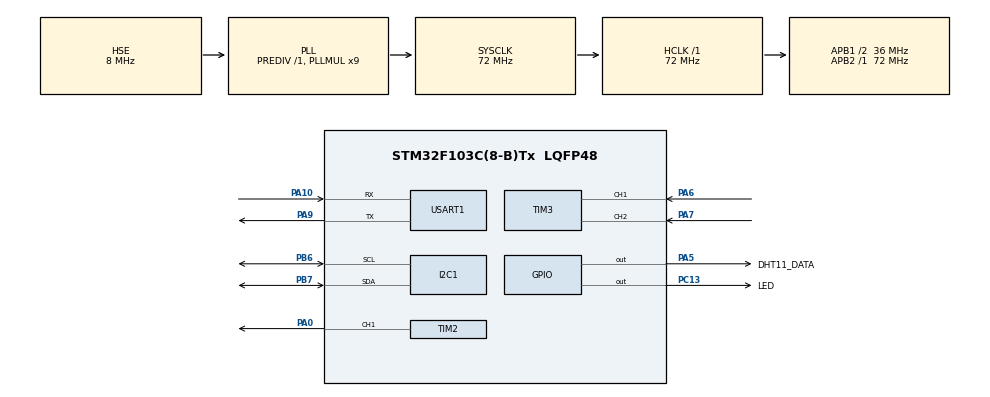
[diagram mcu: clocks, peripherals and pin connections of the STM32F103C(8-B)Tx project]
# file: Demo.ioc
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Dma.Request0=USART1_RX
Dma.Request1=USART1_TX
Dma.USART1_RX.0.Direction=DMA_PERIPH_TO_MEMORY
Dma.USART1_RX.0.Instance=DMA1_Channel5
Dma.USART1_RX.0.MemDataAlignment=DMA_MDATAALIGN_BYTE
Dma.USART1_RX.0.MemInc=DMA_MINC_ENABLE
Dma.USART1_RX.0.Mode=DMA_NORMAL
Dma.USART1_RX.0.PeriphDataAlignment=DMA_PDATAALIGN_BYTE
Dma.USART1_RX.0.PeriphInc=DMA_PINC_DISABLE
Dma.USART1_RX.0.Priority=DMA_PRIORITY_LOW
Dma.USART1_TX.1.Direction=DMA_MEMORY_TO_PERIPH
Dma.USART1_TX.1.Instance=DMA1_Channel4
Dma.USART1_TX.1.MemDataAlignment=DMA_MDATAALIGN_BYTE
Dma.USART1_TX.1.MemInc=DMA_MINC_ENABLE
Dma.USART1_TX.1.Mode=DMA_NORMAL
Dma.USART1_TX.1.PeriphDataAlignment=DMA_PDATAALIGN_BYTE
Dma.USART1_TX.1.PeriphInc=DMA_PINC_DISABLE
Dma.USART1_TX.1.Priority=DMA_PRIORITY_LOW
FREERTOS.BinarySemaphores01=Sem_UartRx,Dynamic,NULL,Available
FREERTOS.Mutexes01=Mutex_State,Dynamic,NULL,Available
FREERTOS.Queues01=Queue_ControlCmd,5,16,1,Dynamic,NULL,NULL
FREERTOS.Tasks01=Task_Safety,40,256,AppTask_Safety,Default,NULL,Dynamic,NULL,NULL;Task_MotorPID,32,256,AppTask_MotorPID,Default,NULL,Dynamic,NULL,NULL;Task_CommRX,24,256,AppTask_CommRX,Default,NULL,Dynamic,NULL,NULL;Task_Sensor,16,256,AppTask_Sensor,Default,NULL,Dynamic,NULL,NULL;Task_Status,8,256,AppTask_Status,Default,NULL,Dynamic,NULL,NULL
FREERTOS.configMINIMAL_STACK_SIZE=256
FREERTOS.configTOTAL_HEAP_SIZE=16384
Mcu.Family=STM32F1
Mcu.Name=STM32F103C(8-B)Tx
Mcu.Package=LQFP48
NVIC.DMA1_Channel4_IRQn=true\:5\:0\:false\:false\:true\:true\:false\:true\:true
NVIC.DMA1_Channel5_IRQn=true\:5\:0\:false\:false\:true\:true\:false\:true\:true
NVIC.PriorityGroup=NVIC_PRIORITYGROUP_4
NVIC.TIM1_UP_IRQn=true\:15\:0\:false\:false\:true\:false\:false\:true\:true
NVIC.TIM4_IRQn=true\:5\:0\:false\:false\:true\:true\:true\:true\:true
NVIC.TimeBase=TIM1_UP_IRQn
NVIC.TimeBaseIP=TIM1
NVIC.USART1_IRQn=true\:5\:0\:false\:false\:true\:true\:true\:true\:true
PA0-WKUP.Signal=S_TIM2_CH1_ETR
PA10.Mode=Asynchronous
PA10.Signal=USART1_RX
PA13.Mode=Serial_Wire
PA13.Signal=SYS_JTMS-SWDIO
PA14.Mode=Serial_Wire
PA14.Signal=SYS_JTCK-SWCLK
PA5.GPIO_Label=DHT11_DATA
PA5.GPIO_ModeDefaultOutputPP=GPIO_MODE_OUTPUT_OD
PA5.GPIO_PuPd=GPIO_PULLUP
PA5.Signal=GPIO_Output
PA6.Signal=S_TIM3_CH1
PA7.Signal=S_TIM3_CH2
PA9.Mode=Asynchronous
PA9.Signal=USART1_TX
PB6.Mode=I2C
PB6.Signal=I2C1_SCL
PB7.Mode=I2C
PB7.Signal=I2C1_SDA
PC13-TAMPER-RTC.GPIO_Label=LED
PC13-TAMPER-RTC.Signal=GPIO_Output
PD0-OSC_IN.Mode=HSE-External-Oscillator
PD0-OSC_IN.Signal=RCC_OSC_IN
PD1-OSC_OUT.Mode=HSE-External-Oscillator
PD1-OSC_OUT.Signal=RCC_OSC_OUT
ProjectManager.HeapSize=0x200
ProjectManager.StackSize=0x400
ProjectManager.TargetToolchain=CMake
RCC.AHBFreq_Value=72000000
RCC.APB1CLKDivider=RCC_HCLK_DIV2
RCC.APB1Freq_Value=36000000
RCC.APB1TimFreq_Value=72000000
RCC.APB2Freq_Value=72000000
RCC.APB2TimFreq_Value=72000000
RCC.HCLKFreq_Value=72000000
RCC.PLLMUL=RCC_PLL_MUL9
RCC.PLLSourceVirtual=RCC_PLLSOURCE_HSE
RCC.SYSCLKFreq_VALUE=72000000
RCC.SYSCLKSource=RCC_SYSCLKSOURCE_PLLCLK
RCC.USBFreq_Value=72000000
SH.S_TIM2_CH1_ETR.0=TIM2_CH1,PWM Generation1 CH1
SH.S_TIM3_CH1.0=TIM3_CH1,Encoder_Interface
SH.S_TIM3_CH2.0=TIM3_CH2,Encoder_Interface
TIM2.Channel-PWM\ Generation1\ CH1=TIM_CHANNEL_1
TIM2.Period=1000-1
TIM2.Prescaler=72-1
TIM3.EncoderMode=TIM_ENCODERMODE_TI12
USART1.VirtualMode=VM_ASYNC
VP_FREERTOS_VS_CMSIS_V2.Mode=CMSIS_V2
VP_SYS_VS_tim1.Mode=TIM1
VP_TIM2_VS_ClockSourceINT.Mode=Internal
VP_TIM4_VS_ClockSourceINT.Mode=Internal
board=custom

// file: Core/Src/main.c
/* USER CODE BEGIN Header */
/**
  ******************************************************************************
  * @file           : main.c
  * @brief          : Main program body
  ******************************************************************************
  * @attention
  *
  * Copyright (c) 2026 STMicroelectronics.
  * All rights reserved.
  *
  * This software is licensed under terms that can be found in the LICENSE file
  * in the root directory of this software component.
  * If no LICENSE file comes with this software, it is provided AS-IS.
  *
  ******************************************************************************
  */
/* USER CODE END Header */
#include "main.h"
#include "cmsis_os.h"
#include "dma.h"
#include "i2c.h"
#include "tim.h"
#include "usart.h"
#include "gpio.h"

/* USER CODE BEGIN Includes */
#include "app_main.h"
#include "motor.h"
/* USER CODE END Includes */

void SystemClock_Config(void);
void MX_FREERTOS_Init(void);

int main(void)
{

  /* MCU Configuration--------------------------------------------------------*/

  /* Reset of all peripherals, Initializes the Flash interface and the Systick. */
  HAL_Init();

  /* Configure the system clock */
  SystemClock_Config();

  /* Initialize all configured peripherals */
  MX_GPIO_Init();
  MX_DMA_Init();
  MX_I2C1_Init();
  MX_TIM2_Init();
  MX_TIM3_Init();
  MX_TIM4_Init();
  MX_USART1_UART_Init();
  /* USER CODE BEGIN 2 */
  App_Init();
  /* USER CODE END 2 */

  /* Init scheduler */
  osKernelInitialize();  /* Call init function for freertos objects (in cmsis_os2.c) */
  MX_FREERTOS_Init();

  /* Start scheduler */
  osKernelStart();

  /* We should never get here as control is now taken by the scheduler */

  /* Infinite loop */
  while (1)
  {

  }
}

void SystemClock_Config(void)
{
  RCC_OscInitTypeDef RCC_OscInitStruct = {0};
  RCC_ClkInitTypeDef RCC_ClkInitStruct = {0};

  /** Initializes the RCC Oscillators according to the specified parameters
  * in the RCC_OscInitTypeDef structure.
  */
  RCC_OscInitStruct.OscillatorType = RCC_OSCILLATORTYPE_HSE;
  RCC_OscInitStruct.HSEState = RCC_HSE_ON;
  RCC_OscInitStruct.HSEPredivValue = RCC_HSE_PREDIV_DIV1;
  RCC_OscInitStruct.HSIState = RCC_HSI_ON;
  RCC_OscInitStruct.PLL.PLLState = RCC_PLL_ON;
  RCC_OscInitStruct.PLL.PLLSource = RCC_PLLSOURCE_HSE;
  RCC_OscInitStruct.PLL.PLLMUL = RCC_PLL_MUL9;
  if (HAL_RCC_OscConfig(&RCC_OscInitStruct) != HAL_OK)
  {
    Error_Handler();
  }

  /** Initializes the CPU, AHB and APB buses clocks
  */
  RCC_ClkInitStruct.ClockType = RCC_CLOCKTYPE_HCLK|RCC_CLOCKTYPE_SYSCLK
                              |RCC_CLOCKTYPE_PCLK1|RCC_CLOCKTYPE_PCLK2;
  RCC_ClkInitStruct.SYSCLKSource = RCC_SYSCLKSOURCE_PLLCLK;
  RCC_ClkInitStruct.AHBCLKDivider = RCC_SYSCLK_DIV1;
  RCC_ClkInitStruct.APB1CLKDivider = RCC_HCLK_DIV2;
  RCC_ClkInitStruct.APB2CLKDivider = RCC_HCLK_DIV1;

  if (HAL_RCC_ClockConfig(&RCC_ClkInitStruct, FLASH_LATENCY_2) != HAL_OK)
  {
    Error_Handler();
  }
}

void HAL_TIM_PeriodElapsedCallback(TIM_HandleTypeDef *htim)
{
  if (htim->Instance == TIM1)
  {
    HAL_IncTick();
  }
  /* USER CODE BEGIN Callback 1 */
  if (htim->Instance == TIM4)
  {
    if (Motor_IsRunning() && !g_sys_state.system_fault)
    {
      Motor_PID_Update();
    }
  }
  /* USER CODE END Callback 1 */
}

void Error_Handler(void)
{
  __disable_irq();
  while (1)
  {
  }
}

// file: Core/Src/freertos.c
/* USER CODE BEGIN Header */
/**
  ******************************************************************************
  * File Name          : freertos.c
  * Description        : Code for freertos applications
  ******************************************************************************
  * @attention
  *
  * Copyright (c) 2026 STMicroelectronics.
  * All rights reserved.
  *
  * This software is licensed under terms that can be found in the LICENSE file
  * in the root directory of this software component.
  * If no LICENSE file comes with this software, it is provided AS-IS.
  *
  ******************************************************************************
  */
/* USER CODE END Header */

#include "FreeRTOS.h"
#include "task.h"
#include "main.h"
#include "app_main.h"
#include "cmsis_os.h"
#include "oled.h"

/* Definitions for Task_Safety */
osThreadId_t Task_SafetyHandle;
const osThreadAttr_t Task_Safety_attributes = {
  .name = "Task_Safety",
  .stack_size = 128 * 4,
  .priority = (osPriority_t) osPriorityHigh,
};
/* Definitions for Task_MotorPID */
osThreadId_t Task_MotorPIDHandle;
const osThreadAttr_t Task_MotorPID_attributes = {
  .name = "Task_MotorPID",
  .stack_size = 256 * 4,
  .priority = (osPriority_t) osPriorityAboveNormal,
};
/* Definitions for Task_CommRX */
osThreadId_t Task_CommRXHandle;
const osThreadAttr_t Task_CommRX_attributes = {
  .name = "Task_CommRX",
  .stack_size = 256 * 4,
  .priority = (osPriority_t) osPriorityNormal,
};
/* Definitions for Task_Sensor */
osThreadId_t Task_SensorHandle;
const osThreadAttr_t Task_Sensor_attributes = {
  .name = "Task_Sensor",
  .stack_size = 128 * 4,
  .priority = (osPriority_t) osPriorityBelowNormal,
};
/* Definitions for Task_Status */
osThreadId_t Task_StatusHandle;
const osThreadAttr_t Task_Status_attributes = {
  .name = "Task_Status",
  .stack_size = 256 * 4,
  .priority = (osPriority_t) osPriorityBelowNormal,
};
/* Definitions for Queue_ControlCmd */
osMessageQueueId_t Queue_ControlCmdHandle;
const osMessageQueueAttr_t Queue_ControlCmd_attributes = {
  .name = "Queue_ControlCmd"
};
/* Definitions for Mutex_State */
osMutexId_t Mutex_StateHandle;
const osMutexAttr_t Mutex_State_attributes = {
  .name = "Mutex_State"
};
/* Definitions for Sem_UartRx */
osSemaphoreId_t Sem_UartRxHandle;
const osSemaphoreAttr_t Sem_UartRx_attributes = {
  .name = "Sem_UartRx"
};

void AppTask_Safety(void *argument);
void AppTask_MotorPID(void *argument);
void AppTask_CommRX(void *argument);
void AppTask_Sensor(void *argument);
void AppTask_Status(void *argument);

void MX_FREERTOS_Init(void); /* (MISRA C 2004 rule 8.1) */

void MX_FREERTOS_Init(void) {
  /* Create the mutex(es) */
  /* creation of Mutex_State */
  Mutex_StateHandle = osMutexNew(&Mutex_State_attributes);

  /* Create the semaphores(s) */
  /* creation of Sem_UartRx */
  Sem_UartRxHandle = osSemaphoreNew(1, 1, &Sem_UartRx_attributes);

  /* Create the queue(s) */
  /* creation of Queue_ControlCmd */
  Queue_ControlCmdHandle = osMessageQueueNew (5, sizeof(ControlMsg_t), &Queue_ControlCmd_attributes);

  /* Create the thread(s) */
  /* creation of Task_Safety */
  Task_SafetyHandle = osThreadNew(AppTask_Safety, NULL, &Task_Safety_attributes);
  if (Task_SafetyHandle == NULL) {
    Device_OLED_Clear();
    Device_OLED_ShowString(0, 0, "ERR: TASK");
    Device_OLED_ShowString(0, 2, "Safety Fail");
    for (;;);
  }

  /* creation of Task_MotorPID */
  Task_MotorPIDHandle = osThreadNew(AppTask_MotorPID, NULL, &Task_MotorPID_attributes);
  if (Task_MotorPIDHandle == NULL) {
    Device_OLED_Clear();
    Device_OLED_ShowString(0, 0, "ERR: TASK");
    Device_OLED_ShowString(0, 2, "MotorPID Fail");
    for (;;);
  }

  /* creation of Task_CommRX */
  Task_CommRXHandle = osThreadNew(AppTask_CommRX, NULL, &Task_CommRX_attributes);
  if (Task_CommRXHandle == NULL) {
    Device_OLED_Clear();
    Device_OLED_ShowString(0, 0, "ERR: TASK");
    Device_OLED_ShowString(0, 2, "CommRX Fail");
    for (;;);
  }

  /* creation of Task_Sensor */
  Task_SensorHandle = osThreadNew(AppTask_Sensor, NULL, &Task_Sensor_attributes);
  if (Task_SensorHandle == NULL) {
    Device_OLED_Clear();
    Device_OLED_ShowString(0, 0, "ERR: TASK");
    Device_OLED_ShowString(0, 2, "Sensor Fail");
    for (;;);
  }

  /* creation of Task_Status */
  Task_StatusHandle = osThreadNew(AppTask_Status, NULL, &Task_Status_attributes);
  if (Task_StatusHandle == NULL) {
    Device_OLED_Clear();
    Device_OLED_ShowString(0, 0, "ERR: TASK");
    Device_OLED_ShowString(0, 2, "Status Fail");
    for (;;);
  }

}
